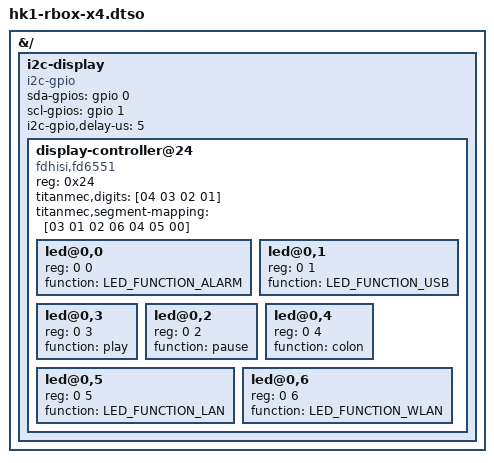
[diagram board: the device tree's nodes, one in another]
/dts-v1/;
/plugin/;

#include <dt-bindings/gpio/gpio.h>
#include <dt-bindings/leds/common.h>

&{/} {

	i2c-display {
		compatible = "i2c-gpio";
		sda-gpios = <&gpio 0 (GPIO_ACTIVE_HIGH | GPIO_OPEN_DRAIN)>;
		scl-gpios = <&gpio 1 (GPIO_ACTIVE_HIGH | GPIO_OPEN_DRAIN)>;
		i2c-gpio,delay-us = <5>;
		#address-cells = <1>;
		#size-cells = <0>;

		display-controller@24 {
			compatible = "fdhisi,fd6551";
			reg = <0x24>;

			titanmec,digits = [04 03 02 01];
			titanmec,segment-mapping = [03 01 02 06 04 05 00];

			#address-cells = <2>;
			#size-cells = <0>;
			
			led@0,0 {
				reg = <0 0>;
				function = LED_FUNCTION_ALARM;
			};
			
			led@0,1 {
				reg = <0 1>;
				function = LED_FUNCTION_USB;
			};
			
			led@0,3 {
				reg = <0 3>;
				function = "play";
			};
			
			led@0,2 {
				reg = <0 2>;
				function = "pause";
			};
			
			led@0,4 {
				reg = <0 4>;
				function = "colon";
			};
			
			led@0,5 {
				reg = <0 5>;
				function = LED_FUNCTION_LAN;
			};
			
			led@0,6 {
				reg = <0 6>;
				function = LED_FUNCTION_WLAN;
			};

		};
	};
};

